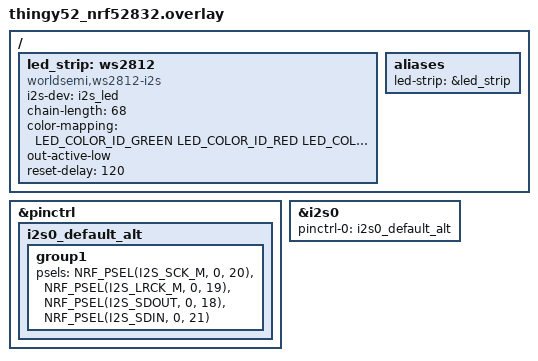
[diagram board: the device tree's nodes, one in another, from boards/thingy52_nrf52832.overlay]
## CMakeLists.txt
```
cmake_minimum_required(VERSION 3.20.0)

find_package(Zephyr REQUIRED HINTS $ENV{ZEPHYR_BASE})

add_subdirectory_ifdef(CONFIG_LED_STRIP drivers/led_strip)

project(periodic_sync)

target_sources(app PRIVATE
  src/main.c
  src/led.c
  )
```

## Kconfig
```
rsource "drivers/led_strip/Kconfig"
```

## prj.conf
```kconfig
CONFIG_BT=y
CONFIG_BT_OBSERVER=y
CONFIG_BT_EXT_ADV=y
CONFIG_BT_DEBUG_LOG=y
CONFIG_BT_DEVICE_NAME="juletre"

CONFIG_BT_RX_STACK_SIZE=4096
CONFIG_THREAD_NAME=y
CONFIG_BT_EXT_SCAN_BUF_SIZE=1650
# Zephyr Bluetooth LE Controller needs 16 event buffers to generate Extended
# Advertising Report for receiving the complete 1650 bytes of data
CONFIG_BT_BUF_EVT_RX_COUNT=16
# Set maximum scan data length for Extended Scanning in Bluetooth LE Controller
CONFIG_BT_CTLR_SCAN_DATA_LEN_MAX=1650
# Increase Zephyr Bluetooth LE Controller Rx buffer to receive complete chain
# of PDUs
CONFIG_BT_CTLR_RX_BUFFERS=9

CONFIG_LOG=y
CONFIG_LED_STRIP=y
CONFIG_LED_STRIP_LOG_LEVEL_DBG=y

CONFIG_I2S=y
CONFIG_WS2812_STRIP=y
CONFIG_WS2812_STRIP_I2S=y

## Enable logging (and redirect printk to log output)
CONFIG_LOG=y
CONFIG_LOG_PRINTK=y
CONFIG_LOG_MODE_IMMEDIATE=y

## Free up UART
CONFIG_SERIAL=y
CONFIG_UART_CONSOLE=y
CONFIG_LOG_BACKEND_UART=n

## Enable logging on RTT
CONFIG_LOG_BACKEND_RTT=y
CONFIG_USE_SEGGER_RTT=y
CONFIG_SEGGER_RTT_BUFFER_SIZE_UP=8192
## Always get the latest logs, even if not read yet
CONFIG_LOG_BACKEND_RTT_MODE_OVERWRITE=y

# CONFIG_REBOOT=n
# CONFIG_RESET_ON_FATAL_ERROR=n
```

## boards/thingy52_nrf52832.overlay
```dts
#include <zephyr/dt-bindings/led/led.h>

&pinctrl {
	i2s0_default_alt: i2s0_default_alt {
		group1 {
			psels = <NRF_PSEL(I2S_SCK_M, 0, 20)>,
				<NRF_PSEL(I2S_LRCK_M, 0, 19)>,
				<NRF_PSEL(I2S_SDOUT, 0, 18)>,
				<NRF_PSEL(I2S_SDIN, 0, 21)>;
		};
	};
};

i2s_led: &i2s0 {
	status = "okay";
	pinctrl-0 = <&i2s0_default_alt>;
	pinctrl-names = "default";
};

/ {
	led_strip: ws2812 {
		compatible = "worldsemi,ws2812-i2s";

		i2s-dev = < &i2s_led >;
		chain-length = <68>; /* arbitrary; change at will */
		color-mapping = <LED_COLOR_ID_GREEN
					LED_COLOR_ID_RED
					LED_COLOR_ID_BLUE>;
		out-active-low;
		reset-delay = <120>;
	};

	aliases {
		led-strip = &led_strip;
	};
};
```

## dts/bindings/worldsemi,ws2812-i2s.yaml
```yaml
# Copyright (c) 2022 Jonathan Rico
# SPDX-License-Identifier: Apache-2.0

description: |
  Worldsemi WS2812 LED strip, I2S binding

  Driver bindings for controlling a WS2812 or compatible LED
  strip with an I2S master.

compatible: "worldsemi,ws2812-i2s"

include: [base.yaml, ws2812.yaml]

properties:

  i2s-dev:
    type: phandle
    required: true
    description: Pointer to the I2S instance.

  out-active-low:
    type: boolean
    required: false
    description: True if the output pin is active low.
```

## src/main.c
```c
#include <zephyr/device.h>
#include <zephyr/devicetree.h>
#include <zephyr/drivers/gpio.h>
#include <zephyr/bluetooth/bluetooth.h>
#include "led.h"

#include <zephyr/logging/log.h>

LOG_MODULE_REGISTER(main, 1);

#define NAME_LEN 30

/* TODO: get this from DT */
#define NUM_LEDS 68
static struct led_data strip[NUM_LEDS];

/* The devicetree node identifier for the "led0" alias. */
#define LED0_NODE DT_ALIAS(led0)

#define HAS_LED     1
static const struct gpio_dt_spec led = GPIO_DT_SPEC_GET(LED0_NODE, gpios);
#define BLINK_ONOFF K_MSEC(500)

static struct k_work_delayable blink_work;
static bool                  led_is_on;

static void blink_timeout(struct k_work *work)
{
	led_is_on = !led_is_on;
	gpio_pin_set(led.port, led.pin, (int)led_is_on);
}

static bool data_cb(struct bt_data *data, void *user_data)
{
	char *name = user_data;
	uint8_t len;

	switch (data->type) {
	case BT_DATA_NAME_SHORTENED:
	case BT_DATA_NAME_COMPLETE:
		len = MIN(data->data_len, NAME_LEN - 1);
		memcpy(name, data->data, len);
		name[len] = '\0';
		return false;
	default:
		return true;
	}
}

static bool led_data_cb(struct bt_data *data, void *user_data)
{
	switch (data->type) {
	case BT_DATA_MANUFACTURER_DATA:
		LOG_HEXDUMP_DBG(data->data, data->data_len, "ad data");
		memset((uint8_t*)strip, 0, sizeof(strip));
		memcpy((uint8_t*)strip, data->data, MIN(data->data_len, sizeof(strip)));
		return false;
	default:
		return true;
	}
}

#define PEER_NAME "santa"
static void scan_recv(const struct bt_le_scan_recv_info *info,
		      struct net_buf_simple *buf)
{
	char le_addr[BT_ADDR_LE_STR_LEN];
	char name[NAME_LEN];

	/* if (info->rssi < -60) return; */

	(void)memset(name, 0, sizeof(name));

	struct net_buf_simple_state state;

	net_buf_simple_save(buf, &state);
	bt_data_parse(buf, data_cb, name);
	net_buf_simple_restore(buf, &state);

	bt_addr_le_to_str(info->addr, le_addr, sizeof(le_addr));
	if (strncmp(PEER_NAME, name, strlen(PEER_NAME))) {
		return;
	}

	printk("[DEVICE]: %s, AD evt type %u, Tx Pwr: %i, RSSI %i %s "
	       "Interval: 0x%04x (%u ms) Len %u\n",
	       le_addr, info->adv_type, info->tx_power, info->rssi, name,
	       info->interval, info->interval * 5 / 4, buf->len);

	bt_data_parse(buf, led_data_cb, NULL);
	/* Switch to using received data */
	/* TODO: switch it back after a timeout. */
	printk("got adv\n");
	led_idle_animation(false);

	k_work_schedule(&blink_work, BLINK_ONOFF);
}

static struct bt_le_scan_cb scan_callbacks = {
	.recv = scan_recv,
};

void main(void)
{
	struct bt_le_scan_param scan_param = {
		.type       = BT_LE_SCAN_TYPE_PASSIVE,
		.options    = BT_LE_SCAN_OPT_FILTER_DUPLICATE,
		.interval   = BT_GAP_SCAN_FAST_INTERVAL,
		.window     = BT_GAP_SCAN_FAST_WINDOW,
	};
	int err;

	/* Configure led strip */
	led_register_data(strip, NUM_LEDS);
	led_idle_animation(true);
	led_thread_start();

	/* Configure on-board LED */
	err = gpio_pin_configure_dt(&led, GPIO_OUTPUT_ACTIVE);
	k_work_init_delayable(&blink_work, blink_timeout);

	/* Initialize the Bluetooth Subsystem */
	err = bt_enable(NULL);
	if (err) {
		printk("Bluetooth init failed (err %d)\n", err);
		return;
	}

	printk("Scan callbacks register...");
	bt_le_scan_cb_register(&scan_callbacks);
	printk("success.\n");

	printk("Start scanning...");
	err = bt_le_scan_start(&scan_param, NULL);
	if (err) {
		printk("failed (err %d)\n", err);
		return;
	}
	printk("success.\n");

	return;
}
```

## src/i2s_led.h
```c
#ifndef I2S_LED_H_
#define I2S_LED_H_

#include <zephyr/drivers/led_strip.h>

int strip_init(void);
int strip_update_rgb(void*, struct led_rgb*, uint16_t);

#endif // I2S_LED_H_
```

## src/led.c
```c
#include <string.h>
#include <zephyr/kernel.h>
#include <zephyr/device.h>
#include <zephyr/drivers/led_strip.h>

#include "led.h"
#include "i2s_led.h"

static struct led_data *data;
static uint16_t data_length;
static bool idle;

#define LED_STACK_SIZE 2000
#define LED_PRIORITY K_PRIO_PREEMPT(0)
#define STRIP_NODE DT_ALIAS(led_strip)
#define STRIP_NUM_PIXELS DT_PROP(DT_ALIAS(led_strip), chain_length)

struct led_rgb pixels[STRIP_NUM_PIXELS];

static const struct device *strip = DEVICE_DT_GET(STRIP_NODE);

K_SEM_DEFINE(data_updated, 0, 1);

void led_entry_point(void *p1, void *p2, void *p3)
{
    ARG_UNUSED(p1);
    ARG_UNUSED(p2);
    ARG_UNUSED(p3);

    while (true) {
        if (idle) {
            /* TODO: show idle animation */
            for (int i=0; i<STRIP_NUM_PIXELS; i++) {
                pixels[i].r = 0;
                pixels[i].g = 0;
                pixels[i].b = 0;
            }
        } else {
            k_sem_take(&data_updated, K_FOREVER);
            /* read out array and set led data colors */
            /* TODO: respect effect flag */
            for (int i=0; i<STRIP_NUM_PIXELS; i++) {
                pixels[i].r = data[i].r;
                pixels[i].g = data[i].g;
                pixels[i].b = data[i].b;
            }
        }

        int rc = led_strip_update_rgb(strip, pixels, STRIP_NUM_PIXELS);
        if (rc) {
            printk("couldn't update strip: %d", rc);
        }
    }
}

K_THREAD_STACK_DEFINE(led_stack_area, LED_STACK_SIZE);
struct k_thread led_thread_data;
static k_tid_t led_tid;

void led_register_data(struct led_data *array, uint16_t len)
{
    if (!array) return;

    data = array;
    data_length = len;
}

void led_thread_start(void)
{
    led_tid = k_thread_create(&led_thread_data, led_stack_area,
                              K_THREAD_STACK_SIZEOF(led_stack_area),
                              led_entry_point,
                              NULL, NULL, NULL,
                              LED_PRIORITY, 0, K_NO_WAIT);
    k_thread_start(led_tid);

    printk("started thread");
}

void led_idle_animation(bool use_idle)
{
    k_sem_give(&data_updated);
    idle = use_idle;
}
```

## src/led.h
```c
#ifndef LED_H_
#define LED_H_

#include <stdint.h>
#include <stdbool.h>


struct led_data {
	uint8_t r;
	uint8_t g;
	uint8_t b;
	uint8_t fx;
} __packed;

void led_register_data(struct led_data *array, uint16_t len);

/* Call led_register_data -before- calling this. */
void led_thread_start(void);

void led_idle_animation(bool use_idle);

#endif // LED_H_
```
